VERSION ""

NS_ :

BS_:

BU_: K182_PACM K43_PSCM K17_EBCM NEO K124_ASCM XXX 1

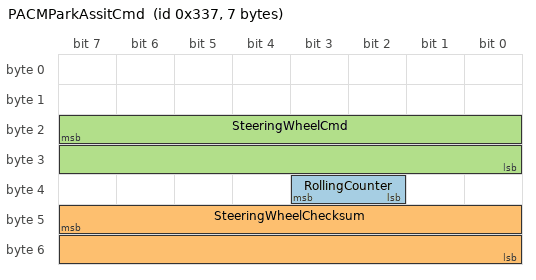
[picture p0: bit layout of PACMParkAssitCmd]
BO_ 823 PACMParkAssitCmd: 7 NEO
 SG_ RollingCounter : 35|2@0+ (1,0) [0|0] "" NEO
 SG_ SteeringWheelChecksum : 47|16@0+ (1,0) [0|0] "" NEO
 SG_ SteeringWheelCmd : 23|16@0+ (1,0) [0|0] "" NEO

BO_ 560 EBCMRegen: 6 K17_EBCM
 SG_ Regen : 1|10@0+ (1,0) [0|0] "" NEO

BO_ 368 EBCMFrictionBrakeStatus: 8 K17_EBCM
 SG_ FrictionBrakePressure : 23|16@0+ (1,0) [0|0] "" NEO

BO_ 789 EBCMFrictionBrakeCmd: 5 K17_EBCM
 SG_ RollingCounter : 33|2@0+ (1,0) [0|0] "" NEO
 SG_ FrictionBrakeMode : 7|4@0+ (1,0) [0|0] "" NEO
 SG_ FrictionBrakeChecksum : 23|16@0+ (1,0) [0|0] "" NEO
 SG_ FrictionBrakeCmd : 3|12@0- (1,0) [0|0] "" NEO

BO_ 1001 Speed and Odometer Data: 8 XXX
 SG_ Speed : 15|16@0+ (1,0) [0|65535] "" XXX
 SG_ Speed  : 31|16@0+ (1,0) [0|65535] "" XXX

BO_TX_BU_ 823 : K43_PSCM,NEO;
BO_TX_BU_ 789 : NEO,K17_EBCM;

CM_ BU_ K182_PACM "Parking Assist Control Module";
CM_ BU_ K43_PSCM "Power Steering Control Module";
CM_ BU_ K17_EBCM "Electronic Brake Control Module";
CM_ BU_ NEO "Comma NEO";
CM_ BU_ K124_ASCM "Active Safety Control Module";
